# BL702 register map
Vendor: Bouffalo Lab; Series: WiFi BT; File version: 1.0
Registers are 32-bit, read-write, reset 0x0 unless marked. A register's access mark holds for its fields unless they carry their own. Offsets are from the block's base; [hi:lo] are bit positions; {n}, {i} and the like mark numbered series.

## DMA — Direct Memory Access module
Base 0x40007000
0x00 DMA_IntStatus
  [7:0] IntStatus
0x04 DMA_IntTCStatus
  [7:0] IntTCStatus
0x08 DMA_IntTCClear
  [7:0] IntTCClear
0x0C DMA_IntErrorStatus
  [7:0] IntErrorStatus
0x10 DMA_IntErrClr
  [7:0] IntErrClr
0x14 DMA_RawIntTCStatus
  [7:0] RawIntTCStatus
0x18 DMA_RawIntErrorStatus
  [7:0] RawIntErrorStatus
0x1C DMA_EnbldChns
  [7:0] EnabledChannels
0x20 DMA_SoftBReq
0x24 DMA_SoftSReq
0x28 DMA_SoftLBReq
0x2C DMA_SoftLSReq
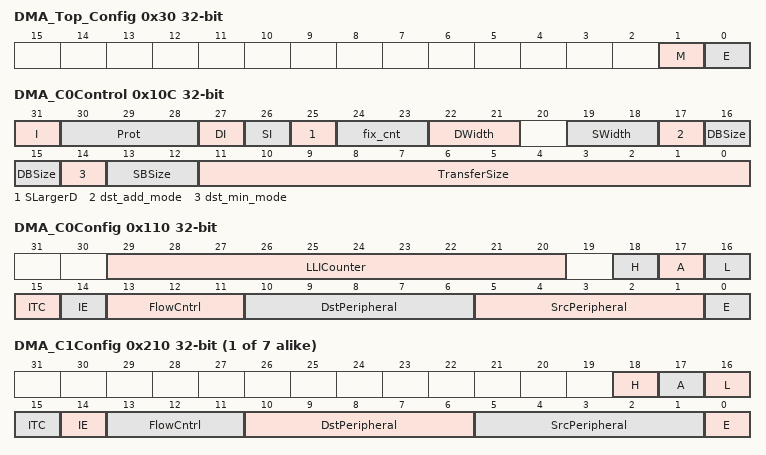
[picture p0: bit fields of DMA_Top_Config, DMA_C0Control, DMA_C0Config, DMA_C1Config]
0x30 DMA_Top_Config
  [1] M, [0] E
0x34 DMA_Sync
{0x100+0x100*i} DMA_C{i}SrcAddr (i=0..7)
  [31:0] SrcAddr
{0x104+0x100*i} DMA_C{i}DstAddr (i=0..7)
  [31:0] DstAddr
0x108 DMA_C0LLI
  [31:0] LLI
0x10C DMA_C0Control
  [31] I, [30:28] Prot, [27] DI, [26] SI, [25] SLargerD, [24:23] fix_cnt, [22:21] DWidth, [19:18] SWidth, [17] dst_add_mode, [16:15] DBSize, [14] dst_min_mode, [13:12] SBSize, [11:0] TransferSize
0x110 DMA_C0Config
  [29:20] LLICounter, [18] H, [17] A, [16] L, [15] ITC, [14] IE, [13:11] FlowCntrl, [10:6] DstPeripheral, [5:1] SrcPeripheral, [0] E
{0x108+0x100*i} DMA_C{i}LLI (i=1..7)
  [31:2] LLI
{0x10C+0x100*i} DMA_C{i}Control (i=1..7)
  [31] I, [30:28] Prot, [27] DI, [26] SI, [24:23] fix_cnt, [23:21] DWidth, [20:18] SWidth, [17] dst_add_mode, [16:15] DBSize, [14] dst_min_mode, [13:12] SBSize, [11:0] TransferSize
{0x110+0x100*i} DMA_C{i}Config (i=1..7)
  [18] H, [17] A, [16] L, [15] ITC, [14] IE, [13:11] FlowCntrl, [10:6] DstPeripheral, [5:1] SrcPeripheral, [0] E

## emac — Ethernet MAC
Base 0x4000D000
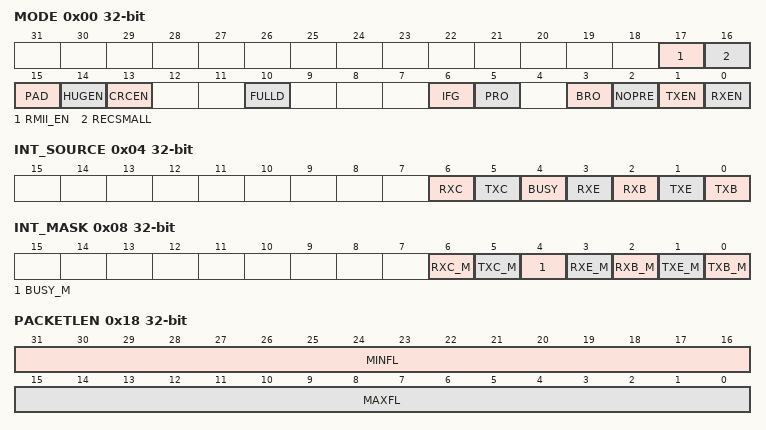
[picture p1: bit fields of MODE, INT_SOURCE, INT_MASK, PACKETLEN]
0x00 MODE
  [17] RMII_EN, [16] RECSMALL, [15] PAD, [14] HUGEN, [13] CRCEN, [10] FULLD, [6] IFG, [5] PRO, [3] BRO, [2] NOPRE, [1] TXEN, [0] RXEN
0x04 INT_SOURCE
  [6] RXC, [5] TXC, [4] BUSY, [3] RXE, [2] RXB, [1] TXE, [0] TXB
0x08 INT_MASK
  [6] RXC_M, [5] TXC_M, [4] BUSY_M, [3] RXE_M, [2] RXB_M, [1] TXE_M, [0] TXB_M
0x0C IPGT
  [6:0] IPGT
0x18 PACKETLEN
  [31:16] MINFL, [15:0] MAXFL
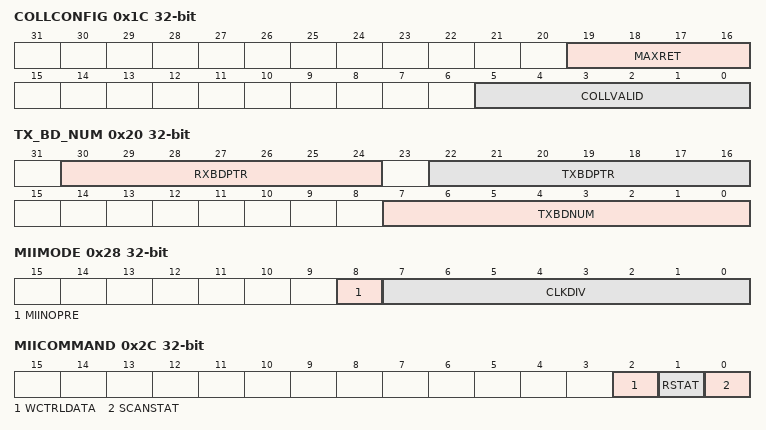
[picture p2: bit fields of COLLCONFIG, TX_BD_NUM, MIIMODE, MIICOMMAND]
0x1C COLLCONFIG
  [19:16] MAXRET, [5:0] COLLVALID
0x20 TX_BD_NUM
  [30:24] RXBDPTR, [22:16] TXBDPTR, [7:0] TXBDNUM
0x28 MIIMODE
  [8] MIINOPRE, [7:0] CLKDIV
0x2C MIICOMMAND
  [2] WCTRLDATA, [1] RSTAT, [0] SCANSTAT
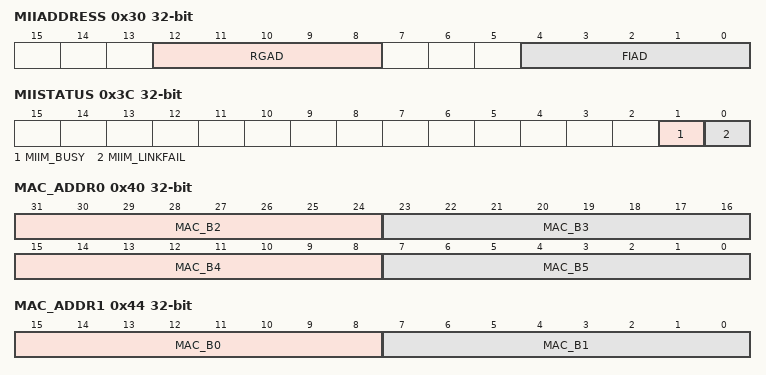
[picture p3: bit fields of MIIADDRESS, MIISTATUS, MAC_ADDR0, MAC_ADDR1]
0x30 MIIADDRESS
  [12:8] RGAD, [4:0] FIAD
0x34 MIITX_DATA
  [15:0] CTRLDATA
0x38 MIIRX_DATA
  [15:0] PRSD
0x3C MIISTATUS
  [1] MIIM_BUSY, [0] MIIM_LINKFAIL
0x40 MAC_ADDR0
  [47-8n:40-8n] MAC_B{n} (n=2..5)
0x44 MAC_ADDR1
  [15:8] MAC_B0, [7:0] MAC_B1
0x48 HASH0_ADDR
  [31:0] HASH0
0x4C HASH1_ADDR
  [31:0] HASH1
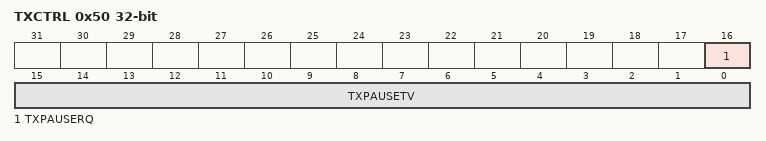
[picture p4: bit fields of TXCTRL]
0x50 TXCTRL
  [16] TXPAUSERQ, [15:0] TXPAUSETV

## USB — Universal Serial Bus host
Base 0x4000D800
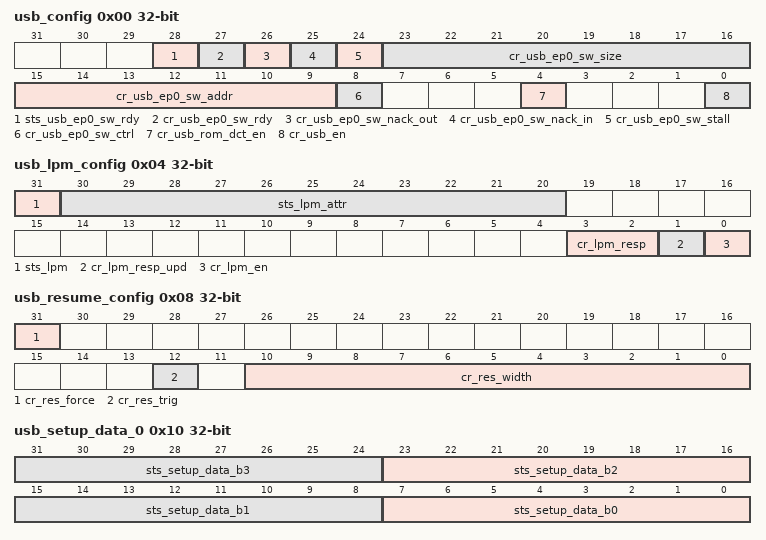
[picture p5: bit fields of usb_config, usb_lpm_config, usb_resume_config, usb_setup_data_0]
0x00 usb_config
  [28] sts_usb_ep0_sw_rdy, [27] cr_usb_ep0_sw_rdy, [26] cr_usb_ep0_sw_nack_out, [25] cr_usb_ep0_sw_nack_in, [24] cr_usb_ep0_sw_stall, [23:16] cr_usb_ep0_sw_size, [15:9] cr_usb_ep0_sw_addr, [8] cr_usb_ep0_sw_ctrl, [4] cr_usb_rom_dct_en, [0] cr_usb_en
0x04 usb_lpm_config
  [31] sts_lpm, [30:20] sts_lpm_attr, [3:2] cr_lpm_resp, [1] cr_lpm_resp_upd, [0] cr_lpm_en
0x08 usb_resume_config
  [31] cr_res_force, [12] cr_res_trig, [10:0] cr_res_width
0x10 usb_setup_data_0
  [8n+7:8n] sts_setup_data_b{n} (n=0..3)
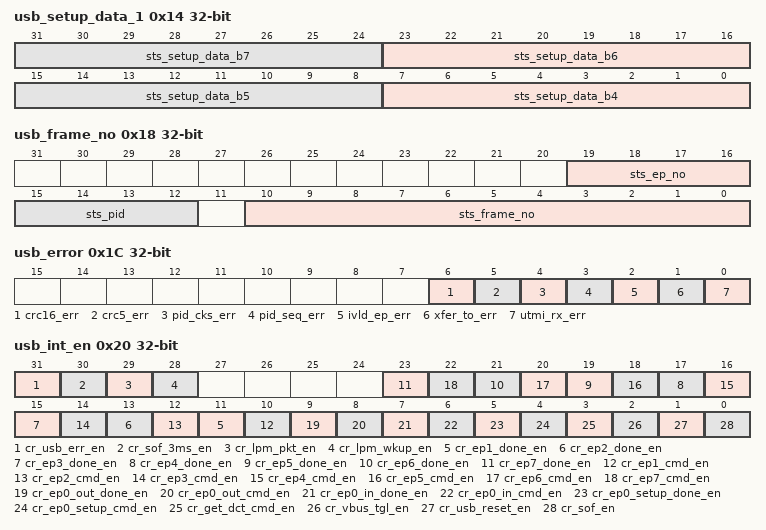
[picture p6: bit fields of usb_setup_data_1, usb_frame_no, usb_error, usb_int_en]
0x14 usb_setup_data_1
  [8n-25:8n-32] sts_setup_data_b{n} (n=4..7)
0x18 usb_frame_no
  [19:16] sts_ep_no, [15:12] sts_pid, [10:0] sts_frame_no
0x1C usb_error
  [6] crc16_err, [5] crc5_err, [4] pid_cks_err, [3] pid_seq_err, [2] ivld_ep_err, [1] xfer_to_err, [0] utmi_rx_err
0x20 usb_int_en — USB interrupt enable
  [31] cr_usb_err_en, [30] cr_sof_3ms_en, [29] cr_lpm_pkt_en, [28] cr_lpm_wkup_en, [2n+9] cr_ep{n}_done_en (n=1..7), [2n+8] cr_ep{n}_cmd_en (n=1..7), [9] cr_ep0_out_done_en, [8] cr_ep0_out_cmd_en, [7] cr_ep0_in_done_en, [6] cr_ep0_in_cmd_en, [5] cr_ep0_setup_done_en, [4] cr_ep0_setup_cmd_en, [3] cr_get_dct_cmd_en, [2] cr_vbus_tgl_en, [1] cr_usb_reset_en, [0] cr_sof_en
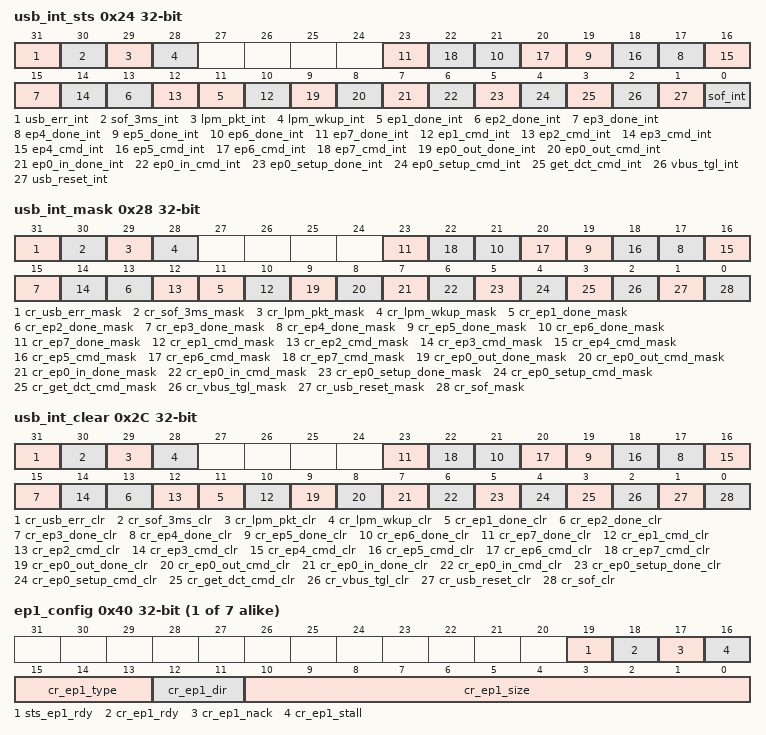
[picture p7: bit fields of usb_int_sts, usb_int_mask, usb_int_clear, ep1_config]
0x24 usb_int_sts — USB interrupt status
  [31] usb_err_int, [30] sof_3ms_int, [29] lpm_pkt_int, [28] lpm_wkup_int, [2n+9] ep{n}_done_int (n=1..7), [2n+8] ep{n}_cmd_int (n=1..7), [9] ep0_out_done_int, [8] ep0_out_cmd_int, [7] ep0_in_done_int, [6] ep0_in_cmd_int, [5] ep0_setup_done_int, [4] ep0_setup_cmd_int, [3] get_dct_cmd_int, [2] vbus_tgl_int, [1] usb_reset_int, [0] sof_int
0x28 usb_int_mask — USB interrupt mask
  [31] cr_usb_err_mask, [30] cr_sof_3ms_mask, [29] cr_lpm_pkt_mask, [28] cr_lpm_wkup_mask, [2n+9] cr_ep{n}_done_mask (n=1..7), [2n+8] cr_ep{n}_cmd_mask (n=1..7), [9] cr_ep0_out_done_mask, [8] cr_ep0_out_cmd_mask, [7] cr_ep0_in_done_mask, [6] cr_ep0_in_cmd_mask, [5] cr_ep0_setup_done_mask, [4] cr_ep0_setup_cmd_mask, [3] cr_get_dct_cmd_mask, [2] cr_vbus_tgl_mask, [1] cr_usb_reset_mask, [0] cr_sof_mask
0x2C usb_int_clear — USB interrupt clear
  [31] cr_usb_err_clr, [30] cr_sof_3ms_clr, [29] cr_lpm_pkt_clr, [28] cr_lpm_wkup_clr, [2n+9] cr_ep{n}_done_clr (n=1..7), [2n+8] cr_ep{n}_cmd_clr (n=1..7), [9] cr_ep0_out_done_clr, [8] cr_ep0_out_cmd_clr, [7] cr_ep0_in_done_clr, [6] cr_ep0_in_cmd_clr, [5] cr_ep0_setup_done_clr, [4] cr_ep0_setup_cmd_clr, [3] cr_get_dct_cmd_clr, [2] cr_vbus_tgl_clr, [1] cr_usb_reset_clr, [0] cr_sof_clr
{0x3C+4i} ep{i}_config (i=1..7)
  [19] sts_ep{i}_rdy, [18] cr_ep{i}_rdy, [17] cr_ep{i}_nack, [16] cr_ep{i}_stall, [15:13] cr_ep{i}_type, [12:11] cr_ep{i}_dir, [10:0] cr_ep{i}_size
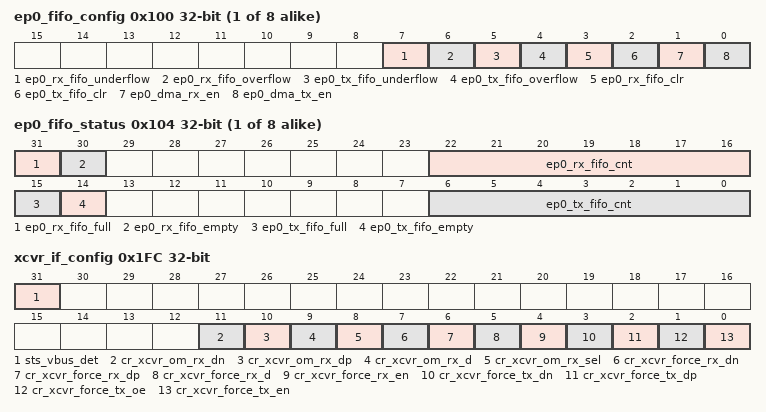
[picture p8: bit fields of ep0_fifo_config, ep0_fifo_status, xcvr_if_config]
{0x100+0x10*i} ep{i}_fifo_config (i=0..7)
  [7] ep{i}_rx_fifo_underflow, [6] ep{i}_rx_fifo_overflow, [5] ep{i}_tx_fifo_underflow, [4] ep{i}_tx_fifo_overflow, [3] ep{i}_rx_fifo_clr, [2] ep{i}_tx_fifo_clr, [1] ep{i}_dma_rx_en, [0] ep{i}_dma_tx_en
{0x104+0x10*i} ep{i}_fifo_status (i=0..7)
  [31] ep{i}_rx_fifo_full, [30] ep{i}_rx_fifo_empty, [22:16] ep{i}_rx_fifo_cnt, [15] ep{i}_tx_fifo_full, [14] ep{i}_tx_fifo_empty, [6:0] ep{i}_tx_fifo_cnt
{0x108+0x10*i} ep{i}_tx_fifo_wdata (i=0..7)
  [7:0] ep{i}_tx_fifo_wdata
{0x10C+0x10*i} ep{i}_rx_fifo_rdata (i=0..7)
  [7:0] ep{i}_rx_fifo_rdata
0x1F0 rsvd_0
0x1F4 rsvd_1
0x1FC xcvr_if_config
  [31] sts_vbus_det, [11] cr_xcvr_om_rx_dn, [10] cr_xcvr_om_rx_dp, [9] cr_xcvr_om_rx_d, [8] cr_xcvr_om_rx_sel, [7] cr_xcvr_force_rx_dn, [6] cr_xcvr_force_rx_dp, [5] cr_xcvr_force_rx_d, [4] cr_xcvr_force_rx_en, [3] cr_xcvr_force_tx_dn, [2] cr_xcvr_force_tx_dp, [1] cr_xcvr_force_tx_oe, [0] cr_xcvr_force_tx_en

## HBN — Hibernate (Deep sleep) control
Base 0x4000F000
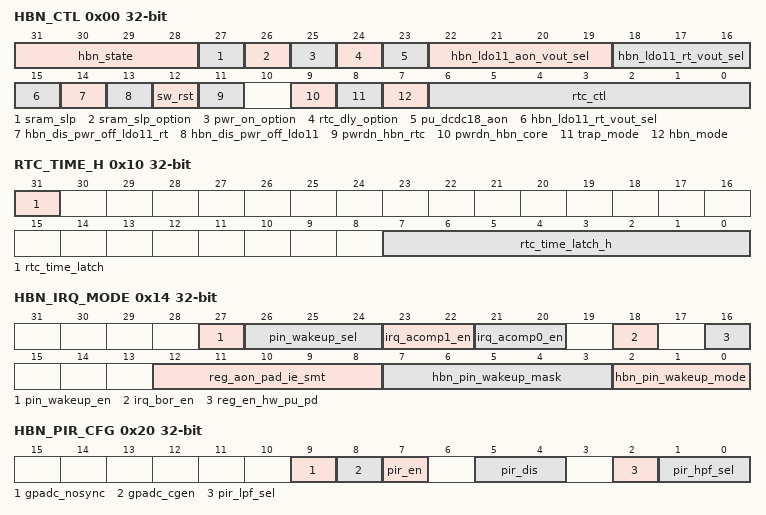
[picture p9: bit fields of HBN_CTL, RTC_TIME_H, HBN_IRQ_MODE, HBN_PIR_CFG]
0x00 HBN_CTL
  [31:28] hbn_state, [27] sram_slp, [26] sram_slp_option, [25] pwr_on_option, [24] rtc_dly_option, [23] pu_dcdc18_aon, [22:19] hbn_ldo11_aon_vout_sel, [18:15] hbn_ldo11_rt_vout_sel, [14] hbn_dis_pwr_off_ldo11_rt, [13] hbn_dis_pwr_off_ldo11, [12] sw_rst, [11] pwrdn_hbn_rtc, [9] pwrdn_hbn_core, [8] trap_mode, [7] hbn_mode, [6:0] rtc_ctl
0x04 HBN_TIME_L
0x08 HBN_TIME_H
  [7:0] hbn_time_h
0x0C RTC_TIME_L
  [31:0] rtc_time_latch_l
0x10 RTC_TIME_H
  [31] rtc_time_latch, [7:0] rtc_time_latch_h
0x14 HBN_IRQ_MODE
  [27] pin_wakeup_en, [26:24] pin_wakeup_sel, [23:22] irq_acomp1_en, [21:20] irq_acomp0_en, [18] irq_bor_en, [16] reg_en_hw_pu_pd, [12:8] reg_aon_pad_ie_smt, [7:3] hbn_pin_wakeup_mask, [2:0] hbn_pin_wakeup_mode
0x18 HBN_IRQ_STAT
  [31:0] irq_stat
0x1C HBN_IRQ_CLR
  [31:0] irq_clr
0x20 HBN_PIR_CFG
  [9] gpadc_nosync, [8] gpadc_cgen, [7] pir_en, [5:4] pir_dis, [2] pir_lpf_sel, [1:0] pir_hpf_sel
0x24 HBN_PIR_VTH
  [13:0] pir_vth
0x28 HBN_PIR_INTERVAL
  [11:0] pir_interval
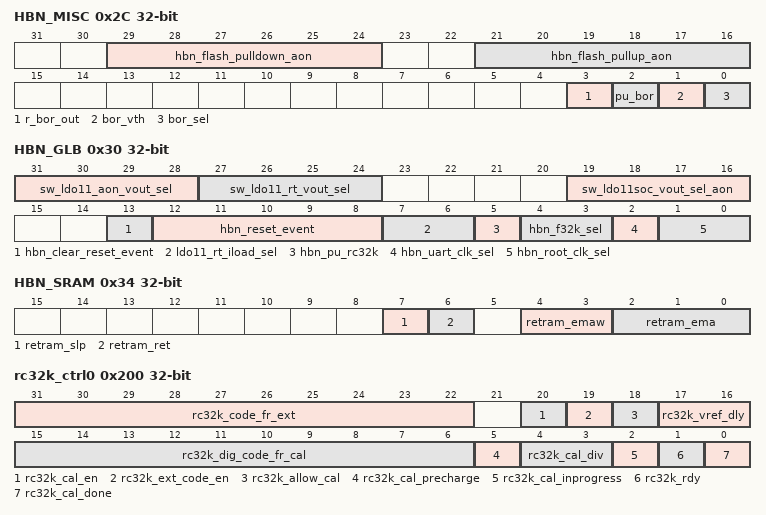
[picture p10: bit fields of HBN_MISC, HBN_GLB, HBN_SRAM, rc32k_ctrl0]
0x2C HBN_MISC
  [29:24] hbn_flash_pulldown_aon, [21:16] hbn_flash_pullup_aon, [3] r_bor_out, [2] pu_bor, [1] bor_vth, [0] bor_sel
0x30 HBN_GLB
  [31:28] sw_ldo11_aon_vout_sel, [27:24] sw_ldo11_rt_vout_sel, [19:16] sw_ldo11soc_vout_sel_aon, [13] hbn_clear_reset_event, [12:8] hbn_reset_event, [7:6] ldo11_rt_iload_sel, [5] hbn_pu_rc32k, [4:3] hbn_f32k_sel, [2] hbn_uart_clk_sel, [1:0] hbn_root_clk_sel
0x34 HBN_SRAM
  [7] retram_slp, [6] retram_ret, [4:3] retram_emaw, [2:0] retram_ema
{0x100+4i} HBN_RSV{i} (i=0..3)
0x200 rc32k_ctrl0
  [31:22] rc32k_code_fr_ext, [20] rc32k_cal_en, [19] rc32k_ext_code_en, [18] rc32k_allow_cal, [17:16] rc32k_vref_dly, [15:6] rc32k_dig_code_fr_cal, [5] rc32k_cal_precharge, [4:3] rc32k_cal_div, [2] rc32k_cal_inprogress, [1] rc32k_rdy, [0] rc32k_cal_done
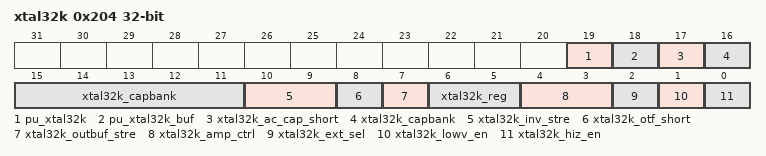
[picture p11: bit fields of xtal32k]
0x204 xtal32k
  [19] pu_xtal32k, [18] pu_xtal32k_buf, [17] xtal32k_ac_cap_short, [16:11] xtal32k_capbank, [10:9] xtal32k_inv_stre, [8] xtal32k_otf_short, [7] xtal32k_outbuf_stre, [6:5] xtal32k_reg, [4:3] xtal32k_amp_ctrl, [2] xtal32k_ext_sel, [1] xtal32k_lowv_en, [0] xtal32k_hiz_en
